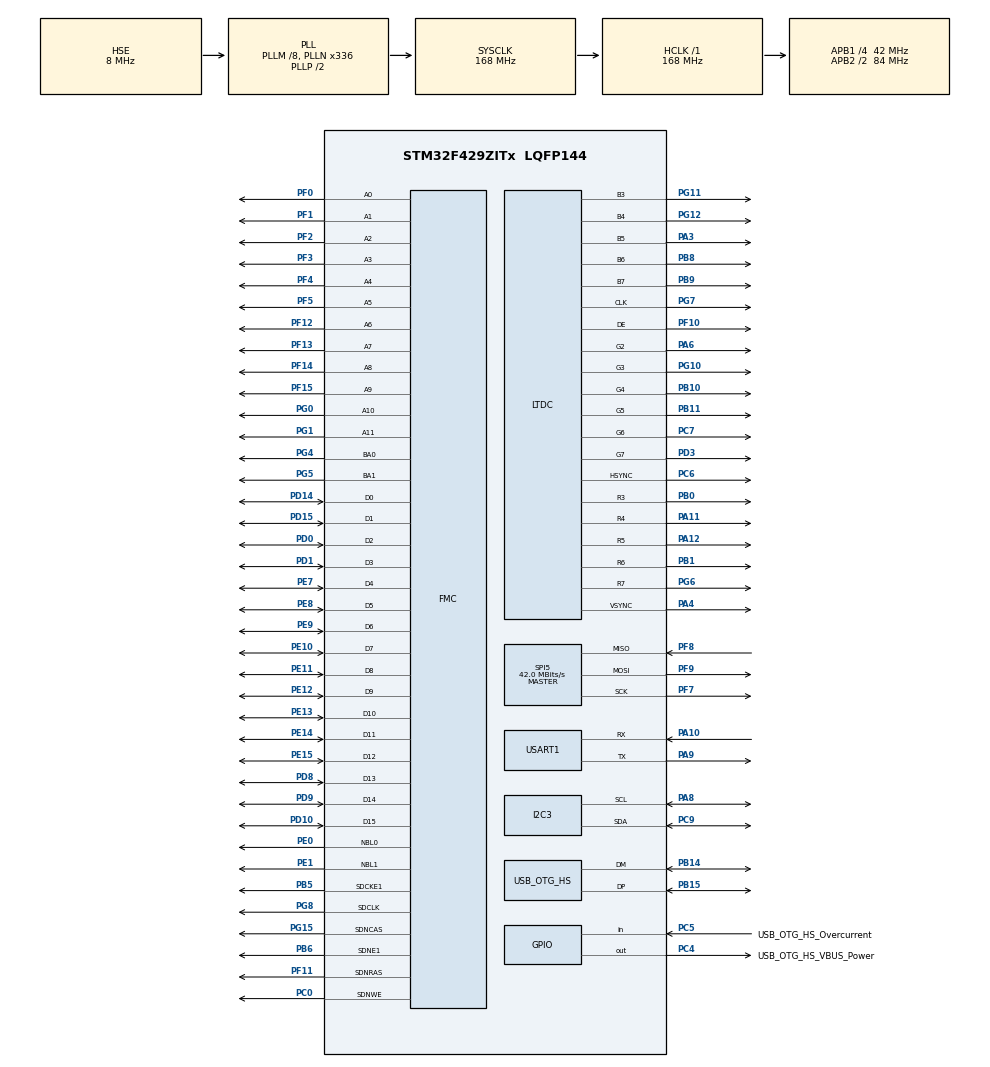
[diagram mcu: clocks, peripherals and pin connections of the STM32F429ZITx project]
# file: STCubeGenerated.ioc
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DMA2D.ColorMode=DMA2D_OUTPUT_RGB565
FMC.CASLatency1=FMC_SDRAM_CAS_LATENCY_3
LTDC.ActiveH=320
LTDC.ActiveW=240
LTDC.HBP=29
LTDC.HFP=2
LTDC.HSync=9
Mcu.Family=STM32F4
Mcu.Name=STM32F429ZITx
Mcu.Package=LQFP144
NVIC.I2C3_ER_IRQn=true\:0\:0\:false\:false\:false\:true\:true\:true
NVIC.I2C3_EV_IRQn=true\:0\:0\:false\:false\:false\:true\:true\:true
NVIC.OTG_HS_EP1_IN_IRQn=true\:0\:0\:false\:false\:false\:true\:true\:true
NVIC.OTG_HS_EP1_OUT_IRQn=true\:0\:0\:false\:false\:false\:true\:true\:true
NVIC.OTG_HS_IRQn=true\:0\:0\:false\:false\:false\:true\:true\:true
NVIC.PriorityGroup=NVIC_PRIORITYGROUP_4
NVIC.TIM5_IRQn=true\:15\:0\:false\:false\:true\:false\:true\:true
NVIC.TimeBase=TIM5_IRQn
NVIC.TimeBaseIP=TIM5
PA10.Mode=Asynchronous
PA10.Signal=USART1_RX
PA11.Mode=RGB565
PA11.Signal=LTDC_R4
PA12.Mode=RGB565
PA12.Signal=LTDC_R5
PA3.Mode=RGB565
PA3.Signal=LTDC_B5
PA4.Mode=RGB565
PA4.Signal=LTDC_VSYNC
PA6.Mode=RGB565
PA6.Signal=LTDC_G2
PA8.Mode=I2C
PA8.Signal=I2C3_SCL
PA9.Mode=Asynchronous
PA9.Signal=USART1_TX
PB0.Mode=RGB565
PB0.Signal=LTDC_R3
PB1.Mode=RGB565
PB1.Signal=LTDC_R6
PB10.Mode=RGB565
PB10.Signal=LTDC_G4
PB11.Mode=RGB565
PB11.Signal=LTDC_G5
PB14.Mode=Host_FS
PB14.Signal=USB_OTG_HS_DM
PB15.Mode=Host_FS
PB15.Signal=USB_OTG_HS_DP
PB5.Mode=SdramChipSelect2_1
PB5.Signal=FMC_SDCKE1
PB6.Mode=SdramChipSelect2_1
PB6.Signal=FMC_SDNE1
PB8.Mode=RGB565
PB8.Signal=LTDC_B6
PB9.Mode=RGB565
PB9.Signal=LTDC_B7
PC0.Signal=FMC_SDNWE
PC4.GPIO_Label=USB_OTG_HS_VBUS_Power
PC4.Signal=GPIO_Output
PC5.GPIO_Label=USB_OTG_HS_Overcurrent
PC5.Signal=GPIO_Input
PC6.Mode=RGB565
PC6.Signal=LTDC_HSYNC
PC7.Mode=RGB565
PC7.Signal=LTDC_G6
PC9.Mode=I2C
PC9.Signal=I2C3_SDA
PD0.Signal=FMC_D2_DA2
PD1.Signal=FMC_D3_DA3
PD10.Signal=FMC_D15_DA15
PD14.Signal=FMC_D0_DA0
PD15.Signal=FMC_D1_DA1
PD3.Mode=RGB565
PD3.Signal=LTDC_G7
PD8.Signal=FMC_D13_DA13
PD9.Signal=FMC_D14_DA14
PE0.Signal=FMC_NBL0
PE1.Signal=FMC_NBL1
PE10.Signal=FMC_D7_DA7
PE11.Signal=FMC_D8_DA8
PE12.Signal=FMC_D9_DA9
PE13.Signal=FMC_D10_DA10
PE14.Signal=FMC_D11_DA11
PE15.Signal=FMC_D12_DA12
PE7.Signal=FMC_D4_DA4
PE8.Signal=FMC_D5_DA5
PE9.Signal=FMC_D6_DA6
PF0.Signal=FMC_A0
PF1.Signal=FMC_A1
PF10.Mode=RGB565
PF10.Signal=LTDC_DE
PF11.Signal=FMC_SDNRAS
PF12.Signal=FMC_A6
PF13.Signal=FMC_A7
PF14.Signal=FMC_A8
PF15.Signal=FMC_A9
PF2.Signal=FMC_A2
PF3.Signal=FMC_A3
PF4.Signal=FMC_A4
PF5.Signal=FMC_A5
PF7.Mode=Full_Duplex_Master
PF7.Signal=SPI5_SCK
PF8.Mode=Full_Duplex_Master
PF8.Signal=SPI5_MISO
PF9.Mode=Full_Duplex_Master
PF9.Signal=SPI5_MOSI
PG0.Signal=FMC_A10
PG1.Signal=FMC_A11
PG10.Mode=RGB565
PG10.Signal=LTDC_G3
PG11.Mode=RGB565
PG11.Signal=LTDC_B3
PG12.Mode=RGB565
PG12.Signal=LTDC_B4
PG15.Signal=FMC_SDNCAS
PG4.Signal=FMC_A14_BA0
PG5.Signal=FMC_A15_BA1
PG6.Mode=RGB565
PG6.Signal=LTDC_R7
PG7.Mode=RGB565
PG7.Signal=LTDC_CLK
PG8.Signal=FMC_SDCLK
PH0/OSC_IN.Mode=HSE-External-Oscillator
PH0/OSC_IN.Signal=RCC_OSC_IN
PH1/OSC_OUT.Mode=HSE-External-Oscillator
PH1/OSC_OUT.Signal=RCC_OSC_OUT
ProjectManager.HeapSize=0x200
ProjectManager.StackSize=0x400
ProjectManager.TargetToolchain=MDK-ARM V5
RCC.48MHZClocksFreq_Value=48000000
RCC.AHBFreq_Value=168000000
RCC.APB1CLKDivider=RCC_HCLK_DIV4
RCC.APB1Freq_Value=42000000
RCC.APB1TimFreq_Value=84000000
RCC.APB2CLKDivider=RCC_HCLK_DIV2
RCC.APB2Freq_Value=84000000
RCC.APB2TimFreq_Value=168000000
RCC.CortexFreq_Value=168000000
RCC.HCLKFreq_Value=168000000
RCC.HSE_VALUE=8000000
RCC.HSI_VALUE=16000000
RCC.LSE_VALUE=32768
RCC.PLLM=8
RCC.PLLN=336
RCC.PLLQ=7
RCC.PLLSAIDivR=RCC_PLLSAIDIVR_8
RCC.PLLSAIN=192
RCC.PLLSAIR=4
RCC.SYSCLKFreq_VALUE=168000000
RCC.SYSCLKSource=RCC_SYSCLKSOURCE_PLLCLK
RCC.VCOOutputFreq_Value=336000000
SH.FMC_A0.0=FMC_A0,12b-sda1
SH.FMC_A1.0=FMC_A1,12b-sda1
SH.FMC_A10.0=FMC_A10,12b-sda1
SH.FMC_A11.0=FMC_A11,12b-sda1
SH.FMC_A14_BA0.0=FMC_BA0,FourSdramBanks1
SH.FMC_A15_BA1.0=FMC_BA1,FourSdramBanks1
SH.FMC_A2.0=FMC_A2,12b-sda1
SH.FMC_A3.0=FMC_A3,12b-sda1
SH.FMC_A4.0=FMC_A4,12b-sda1
SH.FMC_A5.0=FMC_A5,12b-sda1
SH.FMC_A6.0=FMC_A6,12b-sda1
SH.FMC_A7.0=FMC_A7,12b-sda1
SH.FMC_A8.0=FMC_A8,12b-sda1
SH.FMC_A9.0=FMC_A9,12b-sda1
SH.FMC_D0_DA0.0=FMC_D0,sd-16b-d1
SH.FMC_D10_DA10.0=FMC_D10,sd-16b-d1
SH.FMC_D11_DA11.0=FMC_D11,sd-16b-d1
SH.FMC_D12_DA12.0=FMC_D12,sd-16b-d1
SH.FMC_D13_DA13.0=FMC_D13,sd-16b-d1
SH.FMC_D14_DA14.0=FMC_D14,sd-16b-d1
SH.FMC_D15_DA15.0=FMC_D15,sd-16b-d1
SH.FMC_D1_DA1.0=FMC_D1,sd-16b-d1
SH.FMC_D2_DA2.0=FMC_D2,sd-16b-d1
SH.FMC_D3_DA3.0=FMC_D3,sd-16b-d1
SH.FMC_D4_DA4.0=FMC_D4,sd-16b-d1
SH.FMC_D5_DA5.0=FMC_D5,sd-16b-d1
SH.FMC_D6_DA6.0=FMC_D6,sd-16b-d1
SH.FMC_D7_DA7.0=FMC_D7,sd-16b-d1
SH.FMC_D8_DA8.0=FMC_D8,sd-16b-d1
SH.FMC_D9_DA9.0=FMC_D9,sd-16b-d1
SH.FMC_NBL0.0=FMC_NBL0,Sd2ByteEnable1
SH.FMC_NBL1.0=FMC_NBL1,Sd2ByteEnable1
SH.FMC_SDCLK.0=FMC_SDCLK,12b-sda1
SH.FMC_SDNCAS.0=FMC_SDNCAS,12b-sda1
SH.FMC_SDNRAS.0=FMC_SDNRAS,12b-sda1
SH.FMC_SDNWE.0=FMC_SDNWE,12b-sda1
SPI5.BaudRatePrescaler=SPI_BAUDRATEPRESCALER_2
SPI5.CalculateBaudRate=42.0 MBits/s
SPI5.Direction=SPI_DIRECTION_2LINES
SPI5.Mode=SPI_MODE_MASTER
SPI5.VirtualType=VM_MASTER
USART1.VirtualMode=VM_ASYNC
USB_OTG_HS.Sof_enable-Host_FS=DISABLE
USB_OTG_HS.VirtualMode-Host_FS=Host_FS
VP_DMA2D_VS_DMA2D.Mode=DMA2D_Activate
VP_SYS_VS_tim5.Mode=TIM5
board=custom

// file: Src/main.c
/* USER CODE BEGIN Header */
/**
  ******************************************************************************
  * @file           : main.c
  * @brief          : Main program body
  ******************************************************************************
  * @attention
  *
  * Copyright (c) 2024 STMicroelectronics.
  * All rights reserved.
  *
  * This software is licensed under terms that can be found in the LICENSE file
  * in the root directory of this software component.
  * If no LICENSE file comes with this software, it is provided AS-IS.
  *
  ******************************************************************************
  */
/* USER CODE END Header */
#include "main.h"

/* USER CODE BEGIN Includes */
#include "cmsis_os2.h"                  // CMSIS:RTOS2

/* USER CODE END Includes */

DMA2D_HandleTypeDef hdma2d;

I2C_HandleTypeDef hi2c3;

LTDC_HandleTypeDef hltdc;

SPI_HandleTypeDef hspi5;

UART_HandleTypeDef huart1;

HCD_HandleTypeDef hhcd_USB_OTG_HS;

SDRAM_HandleTypeDef hsdram1;

void SystemClock_Config(void);
static void MX_GPIO_Init(void);
static void MX_SPI5_Init(void);
static void MX_USB_OTG_HS_HCD_Init(void);
static void MX_DMA2D_Init(void);
static void MX_FMC_Init(void);
static void MX_LTDC_Init(void);
static void MX_I2C3_Init(void);
static void MX_USART1_UART_Init(void);
/* USER CODE BEGIN PFP */
extern int Init_Thread (void);
/* USER CODE END PFP */

int main(void)
{

  /* MCU Configuration--------------------------------------------------------*/

  /* Reset of all peripherals, Initializes the Flash interface and the Systick. */
  HAL_Init();

  /* Configure the system clock */
  SystemClock_Config();

  /* Initialize all configured peripherals */
  MX_GPIO_Init();
  MX_SPI5_Init();
  MX_USB_OTG_HS_HCD_Init();
  MX_DMA2D_Init();
  MX_FMC_Init();
  MX_LTDC_Init();
  MX_I2C3_Init();
  MX_USART1_UART_Init();
  /* USER CODE BEGIN 2 */

	osKernelInitialize();

	Init_Thread();

	osKernelStart();

  /* USER CODE END 2 */

  /* Infinite loop */
  while (1)
  {

  }
}

void SystemClock_Config(void)
{
  RCC_OscInitTypeDef RCC_OscInitStruct = {0};
  RCC_ClkInitTypeDef RCC_ClkInitStruct = {0};

  /** Configure the main internal regulator output voltage
  */
  __HAL_RCC_PWR_CLK_ENABLE();
  __HAL_PWR_VOLTAGESCALING_CONFIG(PWR_REGULATOR_VOLTAGE_SCALE1);

  /** Initializes the RCC Oscillators according to the specified parameters
  * in the RCC_OscInitTypeDef structure.
  */
  RCC_OscInitStruct.OscillatorType = RCC_OSCILLATORTYPE_HSE;
  RCC_OscInitStruct.HSEState = RCC_HSE_ON;
  RCC_OscInitStruct.PLL.PLLState = RCC_PLL_ON;
  RCC_OscInitStruct.PLL.PLLSource = RCC_PLLSOURCE_HSE;
  RCC_OscInitStruct.PLL.PLLM = 8;
  RCC_OscInitStruct.PLL.PLLN = 336;
  RCC_OscInitStruct.PLL.PLLP = RCC_PLLP_DIV2;
  RCC_OscInitStruct.PLL.PLLQ = 7;
  if (HAL_RCC_OscConfig(&RCC_OscInitStruct) != HAL_OK)
  {
    Error_Handler();
  }

  /** Initializes the CPU, AHB and APB buses clocks
  */
  RCC_ClkInitStruct.ClockType = RCC_CLOCKTYPE_HCLK|RCC_CLOCKTYPE_SYSCLK
                              |RCC_CLOCKTYPE_PCLK1|RCC_CLOCKTYPE_PCLK2;
  RCC_ClkInitStruct.SYSCLKSource = RCC_SYSCLKSOURCE_PLLCLK;
  RCC_ClkInitStruct.AHBCLKDivider = RCC_SYSCLK_DIV1;
  RCC_ClkInitStruct.APB1CLKDivider = RCC_HCLK_DIV4;
  RCC_ClkInitStruct.APB2CLKDivider = RCC_HCLK_DIV2;

  if (HAL_RCC_ClockConfig(&RCC_ClkInitStruct, FLASH_LATENCY_5) != HAL_OK)
  {
    Error_Handler();
  }
}

static void MX_DMA2D_Init(void)
{

  hdma2d.Instance = DMA2D;
  hdma2d.Init.Mode = DMA2D_M2M;
  hdma2d.Init.ColorMode = DMA2D_OUTPUT_RGB565;
  hdma2d.Init.OutputOffset = 0;
  hdma2d.LayerCfg[1].InputOffset = 0;
  hdma2d.LayerCfg[1].InputColorMode = DMA2D_INPUT_RGB565;
  hdma2d.LayerCfg[1].AlphaMode = DMA2D_NO_MODIF_ALPHA;
  hdma2d.LayerCfg[1].InputAlpha = 0;
  if (HAL_DMA2D_Init(&hdma2d) != HAL_OK)
  {
    Error_Handler();
  }
  if (HAL_DMA2D_ConfigLayer(&hdma2d, 1) != HAL_OK)
  {
    Error_Handler();
  }

}

static void MX_I2C3_Init(void)
{

  hi2c3.Instance = I2C3;
  hi2c3.Init.ClockSpeed = 100000;
  hi2c3.Init.DutyCycle = I2C_DUTYCYCLE_2;
  hi2c3.Init.OwnAddress1 = 0;
  hi2c3.Init.AddressingMode = I2C_ADDRESSINGMODE_7BIT;
  hi2c3.Init.DualAddressMode = I2C_DUALADDRESS_DISABLE;
  hi2c3.Init.OwnAddress2 = 0;
  hi2c3.Init.GeneralCallMode = I2C_GENERALCALL_DISABLE;
  hi2c3.Init.NoStretchMode = I2C_NOSTRETCH_DISABLE;
  if (HAL_I2C_Init(&hi2c3) != HAL_OK)
  {
    Error_Handler();
  }

  /** Configure Analogue filter
  */
  if (HAL_I2CEx_ConfigAnalogFilter(&hi2c3, I2C_ANALOGFILTER_ENABLE) != HAL_OK)
  {
    Error_Handler();
  }

  /** Configure Digital filter
  */
  if (HAL_I2CEx_ConfigDigitalFilter(&hi2c3, 0) != HAL_OK)
  {
    Error_Handler();
  }

}

static void MX_LTDC_Init(void)
{

  LTDC_LayerCfgTypeDef pLayerCfg = {0};
  LTDC_LayerCfgTypeDef pLayerCfg1 = {0};

  hltdc.Instance = LTDC;
  hltdc.Init.HSPolarity = LTDC_HSPOLARITY_AL;
  hltdc.Init.VSPolarity = LTDC_VSPOLARITY_AL;
  hltdc.Init.DEPolarity = LTDC_DEPOLARITY_AL;
  hltdc.Init.PCPolarity = LTDC_PCPOLARITY_IPC;
  hltdc.Init.HorizontalSync = 8;
  hltdc.Init.VerticalSync = 3;
  hltdc.Init.AccumulatedHBP = 37;
  hltdc.Init.AccumulatedVBP = 5;
  hltdc.Init.AccumulatedActiveW = 277;
  hltdc.Init.AccumulatedActiveH = 325;
  hltdc.Init.TotalWidth = 279;
  hltdc.Init.TotalHeigh = 327;
  hltdc.Init.Backcolor.Blue = 0;
  hltdc.Init.Backcolor.Green = 0;
  hltdc.Init.Backcolor.Red = 0;
  if (HAL_LTDC_Init(&hltdc) != HAL_OK)
  {
    Error_Handler();
  }
  pLayerCfg.WindowX0 = 0;
  pLayerCfg.WindowX1 = 0;
  pLayerCfg.WindowY0 = 0;
  pLayerCfg.WindowY1 = 0;
  pLayerCfg.PixelFormat = LTDC_PIXEL_FORMAT_ARGB8888;
  pLayerCfg.Alpha = 0;
  pLayerCfg.Alpha0 = 0;
  pLayerCfg.BlendingFactor1 = LTDC_BLENDING_FACTOR1_CA;
  pLayerCfg.BlendingFactor2 = LTDC_BLENDING_FACTOR2_CA;
  pLayerCfg.FBStartAdress = 0;
  pLayerCfg.ImageWidth = 0;
  pLayerCfg.ImageHeight = 0;
  pLayerCfg.Backcolor.Blue = 0;
  pLayerCfg.Backcolor.Green = 0;
  pLayerCfg.Backcolor.Red = 0;
  if (HAL_LTDC_ConfigLayer(&hltdc, &pLayerCfg, 0) != HAL_OK)
  {
    Error_Handler();
  }
  pLayerCfg1.WindowX0 = 0;
  pLayerCfg1.WindowX1 = 0;
  pLayerCfg1.WindowY0 = 0;
  pLayerCfg1.WindowY1 = 0;
  pLayerCfg1.PixelFormat = LTDC_PIXEL_FORMAT_ARGB8888;
  pLayerCfg1.Alpha = 0;
  pLayerCfg1.Alpha0 = 0;
  pLayerCfg1.BlendingFactor1 = LTDC_BLENDING_FACTOR1_CA;
  pLayerCfg1.BlendingFactor2 = LTDC_BLENDING_FACTOR2_CA;
  pLayerCfg1.FBStartAdress = 0;
  pLayerCfg1.ImageWidth = 0;
  pLayerCfg1.ImageHeight = 0;
  pLayerCfg1.Backcolor.Blue = 0;
  pLayerCfg1.Backcolor.Green = 0;
  pLayerCfg1.Backcolor.Red = 0;
  if (HAL_LTDC_ConfigLayer(&hltdc, &pLayerCfg1, 1) != HAL_OK)
  {
    Error_Handler();
  }

}

static void MX_SPI5_Init(void)
{

  /* SPI5 parameter configuration*/
  hspi5.Instance = SPI5;
  hspi5.Init.Mode = SPI_MODE_MASTER;
  hspi5.Init.Direction = SPI_DIRECTION_2LINES;
  hspi5.Init.DataSize = SPI_DATASIZE_8BIT;
  hspi5.Init.CLKPolarity = SPI_POLARITY_LOW;
  hspi5.Init.CLKPhase = SPI_PHASE_1EDGE;
  hspi5.Init.NSS = SPI_NSS_SOFT;
  hspi5.Init.BaudRatePrescaler = SPI_BAUDRATEPRESCALER_2;
  hspi5.Init.FirstBit = SPI_FIRSTBIT_MSB;
  hspi5.Init.TIMode = SPI_TIMODE_DISABLE;
  hspi5.Init.CRCCalculation = SPI_CRCCALCULATION_DISABLE;
  hspi5.Init.CRCPolynomial = 10;
  if (HAL_SPI_Init(&hspi5) != HAL_OK)
  {
    Error_Handler();
  }

}

static void MX_USART1_UART_Init(void)
{

  huart1.Instance = USART1;
  huart1.Init.BaudRate = 115200;
  huart1.Init.WordLength = UART_WORDLENGTH_8B;
  huart1.Init.StopBits = UART_STOPBITS_1;
  huart1.Init.Parity = UART_PARITY_NONE;
  huart1.Init.Mode = UART_MODE_TX_RX;
  huart1.Init.HwFlowCtl = UART_HWCONTROL_NONE;
  huart1.Init.OverSampling = UART_OVERSAMPLING_16;
  if (HAL_UART_Init(&huart1) != HAL_OK)
  {
    Error_Handler();
  }

}

static void MX_USB_OTG_HS_HCD_Init(void)
{

  hhcd_USB_OTG_HS.Instance = USB_OTG_HS;
  hhcd_USB_OTG_HS.Init.Host_channels = 12;
  hhcd_USB_OTG_HS.Init.speed = HCD_SPEED_FULL;
  hhcd_USB_OTG_HS.Init.dma_enable = DISABLE;
  hhcd_USB_OTG_HS.Init.phy_itface = USB_OTG_EMBEDDED_PHY;
  hhcd_USB_OTG_HS.Init.Sof_enable = DISABLE;
  hhcd_USB_OTG_HS.Init.low_power_enable = DISABLE;
  hhcd_USB_OTG_HS.Init.vbus_sensing_enable = DISABLE;
  hhcd_USB_OTG_HS.Init.use_external_vbus = DISABLE;
  if (HAL_HCD_Init(&hhcd_USB_OTG_HS) != HAL_OK)
  {
    Error_Handler();
  }

}

/* FMC initialization function */
static void MX_FMC_Init(void)
{

  FMC_SDRAM_TimingTypeDef SdramTiming = {0};

  /** Perform the SDRAM1 memory initialization sequence
  */
  hsdram1.Instance = FMC_SDRAM_DEVICE;
  /* hsdram1.Init */
  hsdram1.Init.SDBank = FMC_SDRAM_BANK2;
  hsdram1.Init.ColumnBitsNumber = FMC_SDRAM_COLUMN_BITS_NUM_8;
  hsdram1.Init.RowBitsNumber = FMC_SDRAM_ROW_BITS_NUM_12;
  hsdram1.Init.MemoryDataWidth = FMC_SDRAM_MEM_BUS_WIDTH_16;
  hsdram1.Init.InternalBankNumber = FMC_SDRAM_INTERN_BANKS_NUM_4;
  hsdram1.Init.CASLatency = FMC_SDRAM_CAS_LATENCY_3;
  hsdram1.Init.WriteProtection = FMC_SDRAM_WRITE_PROTECTION_DISABLE;
  hsdram1.Init.SDClockPeriod = FMC_SDRAM_CLOCK_DISABLE;
  hsdram1.Init.ReadBurst = FMC_SDRAM_RBURST_DISABLE;
  hsdram1.Init.ReadPipeDelay = FMC_SDRAM_RPIPE_DELAY_0;
  /* SdramTiming */
  SdramTiming.LoadToActiveDelay = 16;
  SdramTiming.ExitSelfRefreshDelay = 16;
  SdramTiming.SelfRefreshTime = 16;
  SdramTiming.RowCycleDelay = 16;
  SdramTiming.WriteRecoveryTime = 16;
  SdramTiming.RPDelay = 16;
  SdramTiming.RCDDelay = 16;

  if (HAL_SDRAM_Init(&hsdram1, &SdramTiming) != HAL_OK)
  {
    Error_Handler( );
  }

}

static void MX_GPIO_Init(void)
{
  GPIO_InitTypeDef GPIO_InitStruct = {0};

  /* GPIO Ports Clock Enable */
  __HAL_RCC_GPIOF_CLK_ENABLE();
  __HAL_RCC_GPIOH_CLK_ENABLE();
  __HAL_RCC_GPIOC_CLK_ENABLE();
  __HAL_RCC_GPIOA_CLK_ENABLE();
  __HAL_RCC_GPIOB_CLK_ENABLE();
  __HAL_RCC_GPIOG_CLK_ENABLE();
  __HAL_RCC_GPIOE_CLK_ENABLE();
  __HAL_RCC_GPIOD_CLK_ENABLE();

  /*Configure GPIO pin Output Level */
  HAL_GPIO_WritePin(USB_OTG_HS_VBUS_Power_GPIO_Port, USB_OTG_HS_VBUS_Power_Pin, GPIO_PIN_RESET);

  /*Configure GPIO pin : USB_OTG_HS_VBUS_Power_Pin */
  GPIO_InitStruct.Pin = USB_OTG_HS_VBUS_Power_Pin;
  GPIO_InitStruct.Mode = GPIO_MODE_OUTPUT_PP;
  GPIO_InitStruct.Pull = GPIO_NOPULL;
  GPIO_InitStruct.Speed = GPIO_SPEED_FREQ_LOW;
  HAL_GPIO_Init(USB_OTG_HS_VBUS_Power_GPIO_Port, &GPIO_InitStruct);

  /*Configure GPIO pin : USB_OTG_HS_Overcurrent_Pin */
  GPIO_InitStruct.Pin = USB_OTG_HS_Overcurrent_Pin;
  GPIO_InitStruct.Mode = GPIO_MODE_INPUT;
  GPIO_InitStruct.Pull = GPIO_NOPULL;
  HAL_GPIO_Init(USB_OTG_HS_Overcurrent_GPIO_Port, &GPIO_InitStruct);

}

void HAL_TIM_PeriodElapsedCallback(TIM_HandleTypeDef *htim)
{
  if (htim->Instance == TIM5) {
    HAL_IncTick();
  }
}

void Error_Handler(void)
{
  __disable_irq();
  while (1)
  {
  }
}
